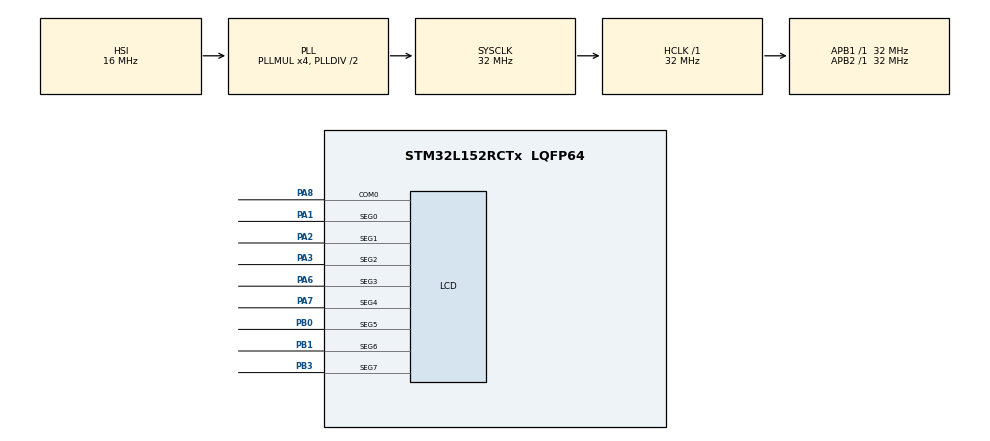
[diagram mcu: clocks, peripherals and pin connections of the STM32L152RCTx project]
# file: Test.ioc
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Mcu.Family=STM32L1
Mcu.Name=STM32L152RCTx
Mcu.Package=LQFP64
NVIC.PriorityGroup=NVIC_PRIORITYGROUP_4
PA1.Mode=SEG0
PA1.Signal=LCD_SEG0
PA2.Mode=SEG1
PA2.Signal=LCD_SEG1
PA3.Mode=SEG2
PA3.Signal=LCD_SEG2
PA6.Mode=SEG3
PA6.Signal=LCD_SEG3
PA7.Mode=SEG4
PA7.Signal=LCD_SEG4
PA8.Mode=Static
PA8.Signal=LCD_COM0
PB0.Mode=SEG5
PB0.Signal=LCD_SEG5
PB1.Mode=SEG6
PB1.Signal=LCD_SEG6
PB3.Mode=SEG7
PB3.Signal=LCD_SEG7
ProjectManager.HeapSize=0x200
ProjectManager.StackSize=0x400
ProjectManager.TargetToolchain=STM32CubeIDE
RCC.48MHZClocksFreq_Value=32000000
RCC.AHBFreq_Value=32000000
RCC.APB1Freq_Value=32000000
RCC.APB1TimFreq_Value=32000000
RCC.APB2Freq_Value=32000000
RCC.APB2TimFreq_Value=32000000
RCC.HCLKFreq_Value=32000000
RCC.HSE_VALUE=24000000
RCC.HSI_VALUE=16000000
RCC.LSE_VALUE=32768
RCC.MSI_VALUE=2097000
RCC.PLLMUL=RCC_PLL_MUL4
RCC.SYSCLKFreq_VALUE=32000000
RCC.SYSCLKSource=RCC_SYSCLKSOURCE_PLLCLK
RCC.VCOOutputFreq_Value=64000000
board=custom

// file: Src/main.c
/* USER CODE BEGIN Header */
/**
  ******************************************************************************
  * @file           : main.c
  * @brief          : Main program body
  ******************************************************************************
  * @attention
  *
  * <h2><center>&copy; Copyright (c) 2019 STMicroelectronics.
  * All rights reserved.</center></h2>
  *
  * This software component is licensed by ST under BSD 3-Clause license,
  * the "License"; You may not use this file except in compliance with the
  * License. You may obtain a copy of the License at:
  *                        opensource.org/licenses/BSD-3-Clause
  *
  ******************************************************************************
  */
/* USER CODE END Header */

#include "main.h"

LCD_HandleTypeDef hlcd;

void SystemClock_Config(void);
static void MX_GPIO_Init(void);
static void MX_LCD_Init(void);

int main(void)
{

  /* MCU Configuration--------------------------------------------------------*/

  /* Reset of all peripherals, Initializes the Flash interface and the Systick. */
  HAL_Init();

  /* Configure the system clock */
  SystemClock_Config();

  /* Initialize all configured peripherals */
  MX_GPIO_Init();
  MX_LCD_Init();
  /* USER CODE BEGIN 2 */
  HAL_LCD_Write(hlcd,hlcd.Instance->RAM[0],  , );
  /* USER CODE END 2 */

  /* Infinite loop */
  while (1)
  {

  }
}

void SystemClock_Config(void)
{
  RCC_OscInitTypeDef RCC_OscInitStruct = {0};
  RCC_ClkInitTypeDef RCC_ClkInitStruct = {0};
  RCC_PeriphCLKInitTypeDef PeriphClkInit = {0};

  /** Configure the main internal regulator output voltage
  */
  __HAL_PWR_VOLTAGESCALING_CONFIG(PWR_REGULATOR_VOLTAGE_SCALE1);
  /** Initializes the CPU, AHB and APB busses clocks
  */
  RCC_OscInitStruct.OscillatorType = RCC_OSCILLATORTYPE_HSI|RCC_OSCILLATORTYPE_LSI;
  RCC_OscInitStruct.HSIState = RCC_HSI_ON;
  RCC_OscInitStruct.HSICalibrationValue = RCC_HSICALIBRATION_DEFAULT;
  RCC_OscInitStruct.LSIState = RCC_LSI_ON;
  RCC_OscInitStruct.PLL.PLLState = RCC_PLL_ON;
  RCC_OscInitStruct.PLL.PLLSource = RCC_PLLSOURCE_HSI;
  RCC_OscInitStruct.PLL.PLLMUL = RCC_PLL_MUL4;
  RCC_OscInitStruct.PLL.PLLDIV = RCC_PLL_DIV2;
  if (HAL_RCC_OscConfig(&RCC_OscInitStruct) != HAL_OK)
  {
    Error_Handler();
  }
  /** Initializes the CPU, AHB and APB busses clocks
  */
  RCC_ClkInitStruct.ClockType = RCC_CLOCKTYPE_HCLK|RCC_CLOCKTYPE_SYSCLK
                              |RCC_CLOCKTYPE_PCLK1|RCC_CLOCKTYPE_PCLK2;
  RCC_ClkInitStruct.SYSCLKSource = RCC_SYSCLKSOURCE_PLLCLK;
  RCC_ClkInitStruct.AHBCLKDivider = RCC_SYSCLK_DIV1;
  RCC_ClkInitStruct.APB1CLKDivider = RCC_HCLK_DIV1;
  RCC_ClkInitStruct.APB2CLKDivider = RCC_HCLK_DIV1;

  if (HAL_RCC_ClockConfig(&RCC_ClkInitStruct, FLASH_LATENCY_1) != HAL_OK)
  {
    Error_Handler();
  }
  PeriphClkInit.PeriphClockSelection = RCC_PERIPHCLK_LCD;
  PeriphClkInit.LCDClockSelection = RCC_RTCCLKSOURCE_LSI;

  if (HAL_RCCEx_PeriphCLKConfig(&PeriphClkInit) != HAL_OK)
  {
    Error_Handler();
  }
}

static void MX_LCD_Init(void)
{

  hlcd.Instance = LCD;
  hlcd.Init.Prescaler = LCD_PRESCALER_1;
  hlcd.Init.Divider = LCD_DIVIDER_16;
  hlcd.Init.Duty = LCD_DUTY_STATIC;
  hlcd.Init.Bias = LCD_BIAS_1_4;
  hlcd.Init.VoltageSource = LCD_VOLTAGESOURCE_INTERNAL;
  hlcd.Init.Contrast = LCD_CONTRASTLEVEL_0;
  hlcd.Init.DeadTime = LCD_DEADTIME_0;
  hlcd.Init.PulseOnDuration = LCD_PULSEONDURATION_0;
  hlcd.Init.MuxSegment = LCD_MUXSEGMENT_DISABLE;
  hlcd.Init.BlinkMode = LCD_BLINKMODE_OFF;
  hlcd.Init.BlinkFrequency = LCD_BLINKFREQUENCY_DIV8;
  if (HAL_LCD_Init(&hlcd) != HAL_OK)
  {
    Error_Handler();
  }

}

static void MX_GPIO_Init(void)
{

  /* GPIO Ports Clock Enable */
  __HAL_RCC_GPIOA_CLK_ENABLE();
  __HAL_RCC_GPIOB_CLK_ENABLE();

}

void Error_Handler(void)
{
}

/************************ (C) COPYRIGHT STMicroelectronics *****END OF FILE****/
